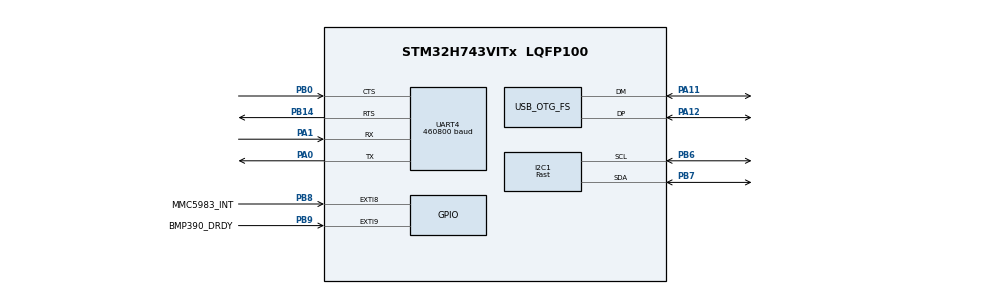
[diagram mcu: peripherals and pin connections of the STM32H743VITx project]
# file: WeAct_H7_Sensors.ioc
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CORTEX_M7.default_mode_Activation=1
Dma.Request0=UART4_RX
Dma.Request1=UART4_TX
Dma.UART4_RX.0.Direction=DMA_PERIPH_TO_MEMORY
Dma.UART4_RX.0.EventEnable=DISABLE
Dma.UART4_RX.0.FIFOMode=DMA_FIFOMODE_DISABLE
Dma.UART4_RX.0.Instance=DMA1_Stream0
Dma.UART4_RX.0.MemDataAlignment=DMA_MDATAALIGN_BYTE
Dma.UART4_RX.0.MemInc=DMA_MINC_ENABLE
Dma.UART4_RX.0.Mode=DMA_NORMAL
Dma.UART4_RX.0.PeriphDataAlignment=DMA_PDATAALIGN_BYTE
Dma.UART4_RX.0.PeriphInc=DMA_PINC_DISABLE
Dma.UART4_RX.0.Polarity=HAL_DMAMUX_REQ_GEN_RISING
Dma.UART4_RX.0.Priority=DMA_PRIORITY_LOW
Dma.UART4_RX.0.RequestNumber=1
Dma.UART4_RX.0.SignalID=NONE
Dma.UART4_RX.0.SyncEnable=DISABLE
Dma.UART4_RX.0.SyncPolarity=HAL_DMAMUX_SYNC_NO_EVENT
Dma.UART4_RX.0.SyncRequestNumber=1
Dma.UART4_RX.0.SyncSignalID=NONE
Dma.UART4_TX.1.Direction=DMA_MEMORY_TO_PERIPH
Dma.UART4_TX.1.EventEnable=DISABLE
Dma.UART4_TX.1.FIFOMode=DMA_FIFOMODE_DISABLE
Dma.UART4_TX.1.Instance=DMA1_Stream1
Dma.UART4_TX.1.MemDataAlignment=DMA_MDATAALIGN_BYTE
Dma.UART4_TX.1.MemInc=DMA_MINC_ENABLE
Dma.UART4_TX.1.Mode=DMA_NORMAL
Dma.UART4_TX.1.PeriphDataAlignment=DMA_PDATAALIGN_BYTE
Dma.UART4_TX.1.PeriphInc=DMA_PINC_DISABLE
Dma.UART4_TX.1.Polarity=HAL_DMAMUX_REQ_GEN_RISING
Dma.UART4_TX.1.Priority=DMA_PRIORITY_LOW
Dma.UART4_TX.1.RequestNumber=1
Dma.UART4_TX.1.SignalID=NONE
Dma.UART4_TX.1.SyncEnable=DISABLE
Dma.UART4_TX.1.SyncPolarity=HAL_DMAMUX_SYNC_NO_EVENT
Dma.UART4_TX.1.SyncRequestNumber=1
Dma.UART4_TX.1.SyncSignalID=NONE
FREERTOS.Tasks01=sensorTask,24,256,StartDefaultTask,Default,NULL,Dynamic,NULL,NULL
I2C1.I2C_Fall_Time=10
I2C1.I2C_Rise_Time=100
I2C1.I2C_Speed_Mode=I2C_Fast
I2C1.Timing=0x00500E31
Mcu.Family=STM32H7
Mcu.Name=STM32H743VITx
Mcu.Package=LQFP100
NVIC.DMA1_Stream0_IRQn=true\:5\:0\:false\:false\:true\:true\:false\:true\:true
NVIC.DMA1_Stream1_IRQn=true\:5\:0\:false\:false\:true\:true\:false\:true\:true
NVIC.EXTI9_5_IRQn=true\:6\:0\:true\:false\:true\:true\:true\:true\:true
NVIC.I2C1_ER_IRQn=true\:5\:0\:true\:false\:true\:true\:true\:true\:true
NVIC.I2C1_EV_IRQn=true\:5\:0\:true\:false\:true\:true\:true\:true\:true
NVIC.OTG_FS_IRQn=true\:5\:0\:false\:false\:true\:true\:false\:true\:true
NVIC.PriorityGroup=NVIC_PRIORITYGROUP_4
NVIC.TIM6_DAC_IRQn=true\:15\:0\:false\:false\:true\:false\:false\:true\:true
NVIC.TimeBase=TIM6_DAC_IRQn
NVIC.TimeBaseIP=TIM6
NVIC.UART4_IRQn=true\:5\:0\:false\:false\:true\:true\:true\:true\:true
PA0.Mode=Asynchronous
PA0.Signal=UART4_TX
PA1.Mode=Asynchronous
PA1.Signal=UART4_RX
PA11.Mode=Device_Only
PA11.Signal=USB_OTG_FS_DM
PA12.Mode=Device_Only
PA12.Signal=USB_OTG_FS_DP
PA13\ (JTMS/SWDIO).Mode=Serial_Wire
PA13\ (JTMS/SWDIO).Signal=DEBUG_JTMS-SWDIO
PA14\ (JTCK/SWCLK).Mode=Serial_Wire
PA14\ (JTCK/SWCLK).Signal=DEBUG_JTCK-SWCLK
PB0.Mode=CTS_RTS
PB0.Signal=UART4_CTS
PB14.Mode=CTS_RTS
PB14.Signal=UART4_RTS
PB6.Mode=I2C
PB6.Signal=I2C1_SCL
PB7.Mode=I2C
PB7.Signal=I2C1_SDA
PB8.GPIO_Label=MMC5983_INT
PB8.GPIO_ModeDefaultEXTI=GPIO_MODE_IT_RISING
PB8.Signal=GPXTI8
PB9.GPIO_Label=BMP390_DRDY
PB9.GPIO_ModeDefaultEXTI=GPIO_MODE_IT_FALLING
PB9.GPIO_PuPd=GPIO_PULLUP
PB9.Signal=GPXTI9
PH0-OSC_IN\ (PH0).Mode=HSE-External-Oscillator
PH0-OSC_IN\ (PH0).Signal=RCC_OSC_IN
PH1-OSC_OUT\ (PH1).Mode=HSE-External-Oscillator
PH1-OSC_OUT\ (PH1).Signal=RCC_OSC_OUT
ProjectManager.HeapSize=0x200
ProjectManager.StackSize=0x400
ProjectManager.TargetToolchain=CMake
RCC.ADCFreq_Value=50390625
RCC.APB1Freq_Value=30000000
RCC.APB2Freq_Value=120000000
RCC.APB3Freq_Value=120000000
RCC.APB4Freq_Value=120000000
RCC.CortexFreq_Value=120000000
RCC.D2PPRE1=RCC_APB1_DIV4
RCC.DIVM1=5
RCC.DIVN1=48
RCC.DIVQ1=5
RCC.HCLKFreq_Value=120000000
RCC.PLL2FRACN=0
RCC.PLL3FRACN=0
RCC.PLLFRACN=0
RCC.PLLSourceVirtual=RCC_PLLSOURCE_HSE
RCC.SYSCLKFreq_VALUE=120000000
RCC.SYSCLKSource=RCC_SYSCLKSOURCE_PLLCLK
RCC.USBFreq_Value=48000000
UART4.BaudRate=460800
USB_DEVICE.CLASS_NAME_FS=CDC
USB_DEVICE.VirtualMode-CDC_FS=Cdc
USB_DEVICE.VirtualModeFS=Cdc_FS
USB_OTG_FS.VirtualMode=Device_Only
VP_FREERTOS_VS_CMSIS_V2.Mode=CMSIS_V2
VP_MEMORYMAP_VS_MEMORYMAP.Mode=CurAppReg
VP_SYS_VS_tim6.Mode=TIM6
VP_USB_DEVICE_VS_USB_DEVICE_CDC_FS.Mode=CDC_FS
board=custom

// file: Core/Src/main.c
/* USER CODE BEGIN Header */
/**
 ******************************************************************************
 * @file           : main.c
 * @brief          : Main program body
 ******************************************************************************
 * @attention
 *
 * Copyright (c) 2026 STMicroelectronics.
 * All rights reserved.
 *
 * This software is licensed under terms that can be found in the LICENSE file
 * in the root directory of this software component.
 * If no LICENSE file comes with this software, it is provided AS-IS.
 *
 ******************************************************************************
 */
/* USER CODE END Header */
#include "main.h"
#include "cmsis_os.h"
#include "dma.h"
#include "i2c.h"
#include "memorymap.h"
#include "usart.h"
#include "usb_device.h"
#include "gpio.h"

void SystemClock_Config(void);
static void MPU_Config(void);
void MX_FREERTOS_Init(void);

int main(void)
{

  /* MPU Configuration--------------------------------------------------------*/
  MPU_Config();

  /* MCU Configuration--------------------------------------------------------*/

  /* Reset of all peripherals, Initializes the Flash interface and the Systick. */
  HAL_Init();

  /* Configure the system clock */
  SystemClock_Config();

  /* Initialize all configured peripherals */
  MX_GPIO_Init();
  MX_DMA_Init();
  MX_I2C1_Init();
  MX_UART4_Init();
  /* USER CODE BEGIN 2 */
  MX_USB_DEVICE_Init();
  /* USER CODE END 2 */

  /* Init scheduler */
  osKernelInitialize();

  /* Call init function for freertos objects (in cmsis_os2.c) */
  MX_FREERTOS_Init();

  /* Start scheduler */
  osKernelStart();

  /* We should never get here as control is now taken by the scheduler */

  /* Infinite loop */
  while (1) {

  }
}

void SystemClock_Config(void)
{
  RCC_OscInitTypeDef RCC_OscInitStruct = {0};
  RCC_ClkInitTypeDef RCC_ClkInitStruct = {0};

  /** Supply configuration update enable
  */
  HAL_PWREx_ConfigSupply(PWR_LDO_SUPPLY);

  /** Configure the main internal regulator output voltage
  */
  __HAL_PWR_VOLTAGESCALING_CONFIG(PWR_REGULATOR_VOLTAGE_SCALE3);

  while(!__HAL_PWR_GET_FLAG(PWR_FLAG_VOSRDY)) {}

  /** Initializes the RCC Oscillators according to the specified parameters
  * in the RCC_OscInitTypeDef structure.
  */
  RCC_OscInitStruct.OscillatorType = RCC_OSCILLATORTYPE_HSE;
  RCC_OscInitStruct.HSEState = RCC_HSE_ON;
  RCC_OscInitStruct.PLL.PLLState = RCC_PLL_ON;
  RCC_OscInitStruct.PLL.PLLSource = RCC_PLLSOURCE_HSE;
  RCC_OscInitStruct.PLL.PLLM = 5;
  RCC_OscInitStruct.PLL.PLLN = 48;
  RCC_OscInitStruct.PLL.PLLP = 2;
  RCC_OscInitStruct.PLL.PLLQ = 5;
  RCC_OscInitStruct.PLL.PLLR = 2;
  RCC_OscInitStruct.PLL.PLLRGE = RCC_PLL1VCIRANGE_2;
  RCC_OscInitStruct.PLL.PLLVCOSEL = RCC_PLL1VCOWIDE;
  RCC_OscInitStruct.PLL.PLLFRACN = 0;
  if (HAL_RCC_OscConfig(&RCC_OscInitStruct) != HAL_OK)
  {
    Error_Handler();
  }

  /** Initializes the CPU, AHB and APB buses clocks
  */
  RCC_ClkInitStruct.ClockType = RCC_CLOCKTYPE_HCLK|RCC_CLOCKTYPE_SYSCLK
                              |RCC_CLOCKTYPE_PCLK1|RCC_CLOCKTYPE_PCLK2
                              |RCC_CLOCKTYPE_D3PCLK1|RCC_CLOCKTYPE_D1PCLK1;
  RCC_ClkInitStruct.SYSCLKSource = RCC_SYSCLKSOURCE_PLLCLK;
  RCC_ClkInitStruct.SYSCLKDivider = RCC_SYSCLK_DIV1;
  RCC_ClkInitStruct.AHBCLKDivider = RCC_HCLK_DIV1;
  RCC_ClkInitStruct.APB3CLKDivider = RCC_APB3_DIV1;
  RCC_ClkInitStruct.APB1CLKDivider = RCC_APB1_DIV4;
  RCC_ClkInitStruct.APB2CLKDivider = RCC_APB2_DIV1;
  RCC_ClkInitStruct.APB4CLKDivider = RCC_APB4_DIV1;

  if (HAL_RCC_ClockConfig(&RCC_ClkInitStruct, FLASH_LATENCY_2) != HAL_OK)
  {
    Error_Handler();
  }
}

 /* MPU Configuration */

void MPU_Config(void)
{
  MPU_Region_InitTypeDef MPU_InitStruct = {0};

  /* Disables the MPU */
  HAL_MPU_Disable();

  /** Initializes and configures the Region and the memory to be protected
  */
  MPU_InitStruct.Enable = MPU_REGION_ENABLE;
  MPU_InitStruct.Number = MPU_REGION_NUMBER0;
  MPU_InitStruct.BaseAddress = 0x0;
  MPU_InitStruct.Size = MPU_REGION_SIZE_4GB;
  MPU_InitStruct.SubRegionDisable = 0x87;
  MPU_InitStruct.TypeExtField = MPU_TEX_LEVEL0;
  MPU_InitStruct.AccessPermission = MPU_REGION_NO_ACCESS;
  MPU_InitStruct.DisableExec = MPU_INSTRUCTION_ACCESS_DISABLE;
  MPU_InitStruct.IsShareable = MPU_ACCESS_SHAREABLE;
  MPU_InitStruct.IsCacheable = MPU_ACCESS_NOT_CACHEABLE;
  MPU_InitStruct.IsBufferable = MPU_ACCESS_NOT_BUFFERABLE;

  HAL_MPU_ConfigRegion(&MPU_InitStruct);
  /* Enables the MPU */
  HAL_MPU_Enable(MPU_PRIVILEGED_DEFAULT);

}

void HAL_TIM_PeriodElapsedCallback(TIM_HandleTypeDef *htim)
{
  if (htim->Instance == TIM6)
  {
    HAL_IncTick();
  }
}

void Error_Handler(void)
{
  __disable_irq();
  while (1) {
  }
}

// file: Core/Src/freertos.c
/* USER CODE BEGIN Header */
/**
  ******************************************************************************
  * File Name          : freertos.c
  * Description        : Code for freertos applications
  ******************************************************************************
  * @attention
  *
  * Copyright (c) 2026 STMicroelectronics.
  * All rights reserved.
  *
  * This software is licensed under terms that can be found in the LICENSE file
  * in the root directory of this software component.
  * If no LICENSE file comes with this software, it is provided AS-IS.
  *
  ******************************************************************************
  */
/* USER CODE END Header */

#include "FreeRTOS.h"
#include "task.h"
#include "main.h"
#include "cmsis_os.h"

/* USER CODE BEGIN Includes */
#include "SensorTask.hpp"
/* USER CODE END Includes */

/* Definitions for sensorTask */
osThreadId_t sensorTaskHandle;
const osThreadAttr_t sensorTask_attributes = {
  .name = "sensorTask",
  .stack_size = 256 * 4,
  .priority = (osPriority_t) osPriorityNormal,
};

void StartDefaultTask(void *argument);

extern void MX_USB_DEVICE_Init(void);
void MX_FREERTOS_Init(void); /* (MISRA C 2004 rule 8.1) */

void MX_FREERTOS_Init(void) {

  /* Create the thread(s) */
  /* creation of sensorTask */
  sensorTaskHandle = osThreadNew(StartDefaultTask, NULL, &sensorTask_attributes);

}

void StartDefaultTask(void *argument)
{
  /* init code for USB_DEVICE */
  MX_USB_DEVICE_Init();
  /* USER CODE BEGIN StartDefaultTask */
    StartSensorTask(argument);
  /* USER CODE END StartDefaultTask */
}
